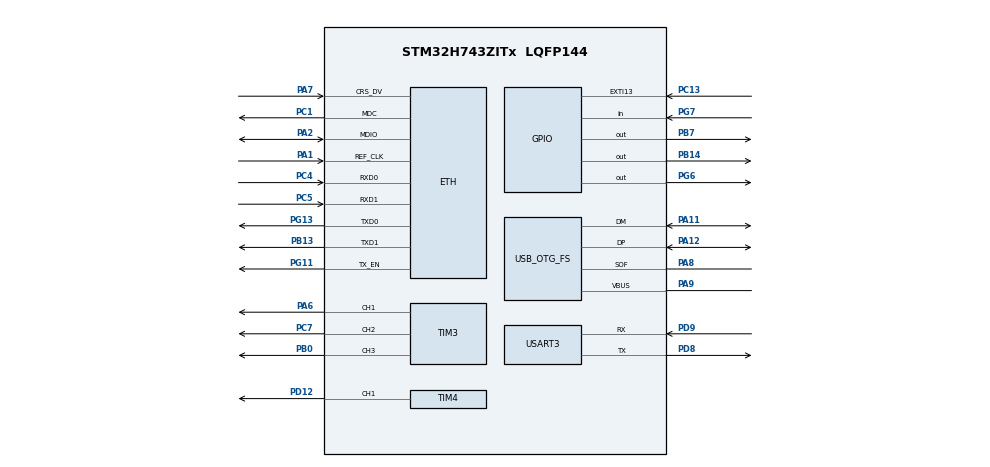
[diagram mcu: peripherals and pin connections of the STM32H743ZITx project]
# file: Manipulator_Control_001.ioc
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ETH.MediaInterface=HAL_ETH_RMII_MODE
Mcu.Family=STM32H7
Mcu.Name=STM32H743ZITx
Mcu.Package=LQFP144
NVIC.PriorityGroup=NVIC_PRIORITYGROUP_4
NVIC.TIM3_IRQn=true\:0\:0\:false\:false\:true\:true\:true
NVIC.TIM4_IRQn=true\:0\:0\:false\:false\:true\:true\:true
NVIC.USART3_IRQn=true\:0\:0\:false\:false\:true\:true\:true
PA1.GPIO_Mode=GPIO_MODE_AF_PP
PA1.GPIO_PuPd=GPIO_NOPULL
PA1.GPIO_Speed=GPIO_SPEED_FREQ_LOW
PA1.Mode=RMII
PA1.Signal=ETH_REF_CLK
PA10.GPIO_Mode=GPIO_MODE_AF_PP
PA10.GPIO_PuPd=GPIO_NOPULL
PA10.GPIO_Speed=GPIO_SPEED_FREQ_LOW
PA10.Signal=USB_OTG_FS_ID
PA11.GPIO_Mode=GPIO_MODE_AF_PP
PA11.GPIO_PuPd=GPIO_NOPULL
PA11.GPIO_Speed=GPIO_SPEED_FREQ_LOW
PA11.Mode=Device_Only
PA11.Signal=USB_OTG_FS_DM
PA12.GPIO_Mode=GPIO_MODE_AF_PP
PA12.GPIO_PuPd=GPIO_NOPULL
PA12.GPIO_Speed=GPIO_SPEED_FREQ_LOW
PA12.Mode=Device_Only
PA12.Signal=USB_OTG_FS_DP
PA2.GPIO_Mode=GPIO_MODE_AF_PP
PA2.GPIO_PuPd=GPIO_NOPULL
PA2.GPIO_Speed=GPIO_SPEED_FREQ_LOW
PA2.Mode=RMII
PA2.Signal=ETH_MDIO
PA6.Signal=S_TIM3_CH1
PA7.GPIO_Mode=GPIO_MODE_AF_PP
PA7.GPIO_PuPd=GPIO_NOPULL
PA7.GPIO_Speed=GPIO_SPEED_FREQ_LOW
PA7.Mode=RMII
PA7.Signal=ETH_CRS_DV
PA8.GPIO_Mode=GPIO_MODE_AF_PP
PA8.GPIO_PuPd=GPIO_NOPULL
PA8.GPIO_Speed=GPIO_SPEED_FREQ_LOW
PA8.Mode=Activate_SOF_FS
PA8.Signal=USB_OTG_FS_SOF
PA9.GPIO_Mode=GPIO_MODE_INPUT
PA9.GPIO_PuPd=GPIO_NOPULL
PA9.Mode=Activate_VBUS
PA9.Signal=USB_OTG_FS_VBUS
PB0.Signal=S_TIM3_CH3
PB13.GPIO_Mode=GPIO_MODE_AF_PP
PB13.GPIO_PuPd=GPIO_NOPULL
PB13.GPIO_Speed=GPIO_SPEED_FREQ_LOW
PB13.Mode=RMII
PB13.Signal=ETH_TXD1
PB14.GPIO_ModeDefaultOutputPP=GPIO_MODE_OUTPUT_PP
PB14.GPIO_PuPd=GPIO_NOPULL
PB14.GPIO_Speed=GPIO_SPEED_FREQ_LOW
PB14.PinState=GPIO_PIN_RESET
PB14.Signal=GPIO_Output
PB7.GPIO_FM7=__NULL
PB7.GPIO_ModeDefaultOutputPP=GPIO_MODE_OUTPUT_PP
PB7.GPIO_PuPd=GPIO_NOPULL
PB7.GPIO_Speed=GPIO_SPEED_FREQ_LOW
PB7.PinState=GPIO_PIN_RESET
PB7.Signal=GPIO_Output
PC1.GPIO_Mode=GPIO_MODE_AF_PP
PC1.GPIO_PuPd=GPIO_NOPULL
PC1.GPIO_Speed=GPIO_SPEED_FREQ_LOW
PC1.Mode=RMII
PC1.Signal=ETH_MDC
PC13.GPIO_ModeDefaultEXTI=GPIO_MODE_IT_RISING
PC13.GPIO_PuPd=GPIO_NOPULL
PC13.Signal=GPXTI13
PC14-OSC32_IN\ (OSC32_IN).Mode=LSE-External-Oscillator
PC14-OSC32_IN\ (OSC32_IN).Signal=RCC_OSC32_IN
PC15-OSC32_OUT\ (OSC32_OUT).Mode=LSE-External-Oscillator
PC15-OSC32_OUT\ (OSC32_OUT).Signal=RCC_OSC32_OUT
PC4.GPIO_Mode=GPIO_MODE_AF_PP
PC4.GPIO_PuPd=GPIO_NOPULL
PC4.GPIO_Speed=GPIO_SPEED_FREQ_LOW
PC4.Mode=RMII
PC4.Signal=ETH_RXD0
PC5.GPIO_Mode=GPIO_MODE_AF_PP
PC5.GPIO_PuPd=GPIO_NOPULL
PC5.GPIO_Speed=GPIO_SPEED_FREQ_LOW
PC5.Mode=RMII
PC5.Signal=ETH_RXD1
PC7.Signal=S_TIM3_CH2
PD12.Signal=S_TIM4_CH1
PD8.GPIO_ModeDefaultPP=GPIO_MODE_AF_PP
PD8.GPIO_PuPd=GPIO_NOPULL
PD8.GPIO_Speed=GPIO_SPEED_FREQ_LOW
PD8.Mode=Asynchronous
PD8.Signal=USART3_TX
PD9.GPIO_ModeDefaultPP=GPIO_MODE_AF_PP
PD9.GPIO_PuPd=GPIO_NOPULL
PD9.GPIO_Speed=GPIO_SPEED_FREQ_LOW
PD9.Mode=Asynchronous
PD9.Signal=USART3_RX
PG11.GPIO_Mode=GPIO_MODE_AF_PP
PG11.GPIO_PuPd=GPIO_NOPULL
PG11.GPIO_Speed=GPIO_SPEED_FREQ_LOW
PG11.Mode=RMII
PG11.Signal=ETH_TX_EN
PG13.GPIO_Mode=GPIO_MODE_AF_PP
PG13.GPIO_PuPd=GPIO_NOPULL
PG13.GPIO_Speed=GPIO_SPEED_FREQ_LOW
PG13.Mode=RMII
PG13.Signal=ETH_TXD0
PG6.GPIO_ModeDefaultOutputPP=GPIO_MODE_OUTPUT_PP
PG6.GPIO_PuPd=GPIO_NOPULL
PG6.GPIO_Speed=GPIO_SPEED_FREQ_LOW
PG6.PinState=GPIO_PIN_RESET
PG6.Signal=GPIO_Output
PG7.GPIO_Mode=GPIO_MODE_INPUT
PG7.GPIO_PuPd=GPIO_NOPULL
PG7.Signal=GPIO_Input
PH0-OSC_IN\ (PH0).Mode=HSE-External-Clock-Source
PH0-OSC_IN\ (PH0).Signal=RCC_OSC_IN
PH1-OSC_OUT\ (PH1).Mode=HSE-External-Clock-Source
PH1-OSC_OUT\ (PH1).Signal=RCC_OSC_OUT
ProjectManager.HeapSize=0x200
ProjectManager.StackSize=0x400
ProjectManager.TargetToolchain=STM32CubeIDE
RCC.48MHZClocksFreq_Value=24000000
RCC.ADCFreq_Value=16125000
RCC.AHBFreq_Value=216000000
RCC.APB1CLKDivider=RCC_HCLK_DIV4
RCC.APB1Freq_Value=96000000
RCC.APB1TimFreq_Value=108000000
RCC.APB2CLKDivider=RCC_HCLK_DIV2
RCC.APB2Freq_Value=96000000
RCC.APB2TimFreq_Value=216000000
RCC.APB3Freq_Value=96000000
RCC.APB4Freq_Value=96000000
RCC.CortexFreq_Value=96000000
RCC.DIVM1=1
RCC.DIVN1=24
RCC.DIVQ1=4
RCC.HCLKFreq_Value=96000000
RCC.HSE_VALUE=8000000
RCC.HSI_VALUE=64000000
RCC.PLLM=25
RCC.PLLMUL=RCC_PLL_MUL9
RCC.PLLN=432
RCC.PLLQ=9
RCC.PRESCALERUSB=RCC_USBCLKSOURCE_PLL_DIV1_5
RCC.SYSCLKFreq_VALUE=96000000
RCC.SYSCLKSource=RCC_SYSCLKSOURCE_PLLCLK
RCC.SYSCLKSourceVirtual=RCC_SYSCLKSOURCE_PLLCLK
RCC.USBFreq_Value=48000000
RCC.VCOOutputFreq_Value=432000000
SH.S_TIM3_CH1.0=TIM3_CH1,PWM Generation1 CH1
SH.S_TIM3_CH2.0=TIM3_CH2,PWM Generation2 CH2
SH.S_TIM3_CH3.0=TIM3_CH3,PWM Generation3 CH3
SH.S_TIM4_CH1.0=TIM4_CH1,PWM Generation1 CH1
TIM3.AutoReloadPreload=TIM_AUTORELOAD_PRELOAD_ENABLE
TIM3.Channel-PWM\ Generation1\ CH1=TIM_CHANNEL_1
TIM3.Channel-PWM\ Generation2\ CH2=TIM_CHANNEL_2
TIM3.Channel-PWM\ Generation3\ CH3=TIM_CHANNEL_3
TIM4.AutoReloadPreload=TIM_AUTORELOAD_PRELOAD_ENABLE
TIM4.Channel-PWM\ Generation1\ CH1=TIM_CHANNEL_1
USART3.VirtualMode-Asynchronous=VM_ASYNC
USB_OTG_FS.VirtualMode=Device_Only
VP_TIM3_VS_ClockSourceINT.Mode=Internal
VP_TIM4_VS_ClockSourceINT.Mode=Internal
board=NUCLEO-H743ZI

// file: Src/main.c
/* USER CODE BEGIN Header */
/**
  ******************************************************************************
  * @file           : main.c
  * @brief          : Main program body
  ******************************************************************************
  * @attention
  *
  * <h2><center>&copy; Copyright (c) 2019 STMicroelectronics.
  * All rights reserved.</center></h2>
  *
  * This software component is licensed by ST under BSD 3-Clause license,
  * the "License"; You may not use this file except in compliance with the
  * License. You may obtain a copy of the License at:
  *                        opensource.org/licenses/BSD-3-Clause
  *
  ******************************************************************************
  */
/* USER CODE END Header */

#include "main.h"
#include "eth.h"
#include "tim.h"
#include "usart.h"
#include "gpio.h"

/* USER CODE BEGIN Includes */
#include "servo_ctrl.h"
#include "stepper_ctrl.h"
/* USER CODE END Includes */

void SystemClock_Config(void);

int main(void)
{

  /* MCU Configuration--------------------------------------------------------*/

  /* Reset of all peripherals, Initializes the Flash interface and the Systick. */
  HAL_Init();

  /* Configure the system clock */
  SystemClock_Config();

  /* Initialize all configured peripherals */
  MX_GPIO_Init();
 // MX_ETH_Init();
  MX_USART3_UART_Init();
 // MX_USB_OTG_FS_PCD_Init();
  MX_TIM3_Init();
  MX_TIM4_Init();
  /* USER CODE BEGIN 2 */
  servo_initialize(0);
  //servo_initialize(1);
  //rx_setting();
  /* USER CODE END 2 */

  /* Infinite loop */
  while (1)
  {

	  servo_goto(0, 0, 70);
	 // servo_goto(1, 0, 30);
	  while(1)
	  {
		  if (!servo_is_running(0))
		  {
			  break; // break out from infinite loop
		  }
	  }
	  HAL_Delay(3000);
	  servo_goto(0, 1800, 30);
	 // servo_goto(1, 1800, 70);
	  while(1)
	  {
		  if (!servo_is_running(0))
		  {
			  break;
		  }
	  }
	  HAL_Delay(3000);
  }
}

void SystemClock_Config(void)
{
  RCC_OscInitTypeDef RCC_OscInitStruct = {0};
  RCC_ClkInitTypeDef RCC_ClkInitStruct = {0};
  RCC_PeriphCLKInitTypeDef PeriphClkInitStruct = {0};

  /** Supply configuration update enable
  */
  HAL_PWREx_ConfigSupply(PWR_LDO_SUPPLY);
  /** Configure the main internal regulator output voltage
  */
  __HAL_PWR_VOLTAGESCALING_CONFIG(PWR_REGULATOR_VOLTAGE_SCALE3);

  while(!__HAL_PWR_GET_FLAG(PWR_FLAG_VOSRDY)) {}
  /** Initializes the CPU, AHB and APB busses clocks
  */
  RCC_OscInitStruct.OscillatorType = RCC_OSCILLATORTYPE_HSE;
  RCC_OscInitStruct.HSEState = RCC_HSE_BYPASS;
  RCC_OscInitStruct.PLL.PLLState = RCC_PLL_ON;
  RCC_OscInitStruct.PLL.PLLSource = RCC_PLLSOURCE_HSE;
  RCC_OscInitStruct.PLL.PLLM = 1;
  RCC_OscInitStruct.PLL.PLLN = 24;
  RCC_OscInitStruct.PLL.PLLP = 2;
  RCC_OscInitStruct.PLL.PLLQ = 4;
  RCC_OscInitStruct.PLL.PLLR = 2;
  RCC_OscInitStruct.PLL.PLLRGE = RCC_PLL1VCIRANGE_3;
  RCC_OscInitStruct.PLL.PLLVCOSEL = RCC_PLL1VCOWIDE;
  RCC_OscInitStruct.PLL.PLLFRACN = 0;
  if (HAL_RCC_OscConfig(&RCC_OscInitStruct) != HAL_OK)
  {
    Error_Handler();
  }
  /** Initializes the CPU, AHB and APB busses clocks
  */
  RCC_ClkInitStruct.ClockType = RCC_CLOCKTYPE_HCLK|RCC_CLOCKTYPE_SYSCLK
                              |RCC_CLOCKTYPE_PCLK1|RCC_CLOCKTYPE_PCLK2
                              |RCC_CLOCKTYPE_D3PCLK1|RCC_CLOCKTYPE_D1PCLK1;
  RCC_ClkInitStruct.SYSCLKSource = RCC_SYSCLKSOURCE_PLLCLK;
  RCC_ClkInitStruct.SYSCLKDivider = RCC_SYSCLK_DIV1;
  RCC_ClkInitStruct.AHBCLKDivider = RCC_HCLK_DIV1;
  RCC_ClkInitStruct.APB3CLKDivider = RCC_APB3_DIV1;
  RCC_ClkInitStruct.APB1CLKDivider = RCC_APB1_DIV1;
  RCC_ClkInitStruct.APB2CLKDivider = RCC_APB2_DIV1;
  RCC_ClkInitStruct.APB4CLKDivider = RCC_APB4_DIV1;

  if (HAL_RCC_ClockConfig(&RCC_ClkInitStruct, FLASH_LATENCY_1) != HAL_OK)
  {
    Error_Handler();
  }
  PeriphClkInitStruct.PeriphClockSelection = RCC_PERIPHCLK_USART3|RCC_PERIPHCLK_USB;
  PeriphClkInitStruct.Usart234578ClockSelection = RCC_USART234578CLKSOURCE_D2PCLK1;
  PeriphClkInitStruct.UsbClockSelection = RCC_USBCLKSOURCE_PLL;
  if (HAL_RCCEx_PeriphCLKConfig(&PeriphClkInitStruct) != HAL_OK)
  {
    Error_Handler();
  }
  /** Enable USB Voltage detector
  */
  HAL_PWREx_EnableUSBVoltageDetector();
}

void Error_Handler(void)
{
}

/************************ (C) COPYRIGHT STMicroelectronics *****END OF FILE****/
